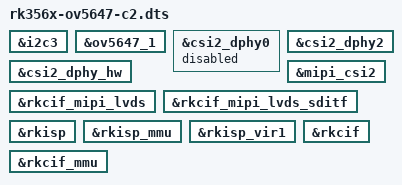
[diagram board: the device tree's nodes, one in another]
/dts-v1/;
/plugin/;

#include <dt-bindings/gpio/gpio.h>
#include <dt-bindings/pinctrl/rockchip.h>

/ {
	fragment@0 {
		target = <&i2c3>;

		__overlay__ {
			status = "okay";
		};
	};

	fragment@1 {
		target = <&ov5647_1>;

		__overlay__ {
			status = "okay";
		};
	};

	fragment@2 {
		target = <&csi2_dphy0>;

		__overlay__ {
			status = "disabled";
		};
	};

	fragment@3 {
		target = <&csi2_dphy2>;

		__overlay__ {
			status = "okay";
		};
	};

	fragment@4 {
		target = <&csi2_dphy_hw>;

		__overlay__ {
			status = "okay";
		};
	};

	fragment@5 {
		target = <&mipi_csi2>;

		__overlay__ {
			status = "okay";
		};
	};

	fragment@6 {
		target = <&rkcif_mipi_lvds>;

		__overlay__ {
			status = "okay";
		};
	};

	fragment@7 {
		target = <&rkcif_mipi_lvds_sditf>;

		__overlay__ {
			status = "okay";
		};
	};

	fragment@8 {
		target = <&rkisp>;

		__overlay__ {
			status = "okay";
		};
	};

	fragment@9 {
		target = <&rkisp_mmu>;
		__overlay__ {
			status = "okay";
		};
	};

	fragment@10 {
		target = <&rkisp_vir1>;

		__overlay__ {
        		status = "okay";
		};
	};

	fragment@11 {
		target = <&rkcif>;

		__overlay__ {
			status = "okay";
		};
	};

	fragment@12 {
		target = <&rkcif_mmu>;

		__overlay__ {
			status = "okay";
		};
	};
};
